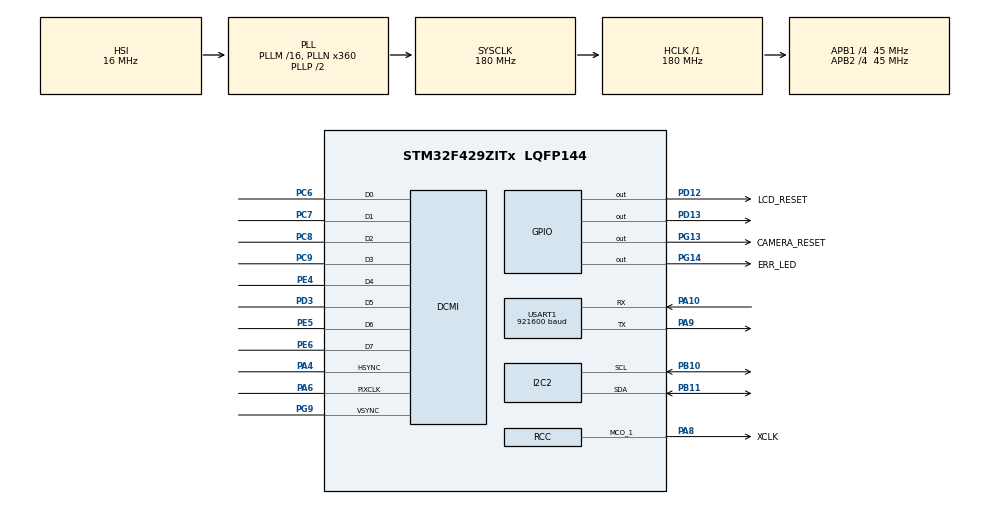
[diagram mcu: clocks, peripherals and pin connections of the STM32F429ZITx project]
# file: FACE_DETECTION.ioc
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DCMI.PCKPolarity=DCMI_PCKPOLARITY_RISING
DCMI.VSPolarity=DCMI_VSPOLARITY_HIGH
Dma.DCMI.0.Direction=DMA_PERIPH_TO_MEMORY
Dma.DCMI.0.FIFOMode=DMA_FIFOMODE_DISABLE
Dma.DCMI.0.Instance=DMA2_Stream1
Dma.DCMI.0.MemDataAlignment=DMA_MDATAALIGN_WORD
Dma.DCMI.0.MemInc=DMA_MINC_ENABLE
Dma.DCMI.0.Mode=DMA_NORMAL
Dma.DCMI.0.PeriphDataAlignment=DMA_PDATAALIGN_WORD
Dma.DCMI.0.PeriphInc=DMA_PINC_DISABLE
Dma.DCMI.0.Priority=DMA_PRIORITY_HIGH
Dma.Request0=DCMI
Mcu.Family=STM32F4
Mcu.Name=STM32F429ZITx
Mcu.Package=LQFP144
NVIC.DMA2_Stream1_IRQn=true\:0\:0\:false\:false\:true\:false\:true
NVIC.PriorityGroup=NVIC_PRIORITYGROUP_0
PA10.Mode=Asynchronous
PA10.Signal=USART1_RX
PA13.Mode=Serial_Wire
PA13.Signal=SYS_JTMS-SWDIO
PA14.Mode=Serial_Wire
PA14.Signal=SYS_JTCK-SWCLK
PA4.GPIO_Speed=GPIO_SPEED_FREQ_HIGH
PA4.Mode=Slave_8_bits_External_Synchro
PA4.Signal=DCMI_HSYNC
PA6.GPIO_Speed=GPIO_SPEED_FREQ_HIGH
PA6.Mode=Slave_8_bits_External_Synchro
PA6.Signal=DCMI_PIXCLK
PA8.GPIO_Label=XCLK
PA8.GPIO_Speed=GPIO_SPEED_FREQ_HIGH
PA8.Mode=Clock-out-1
PA8.Signal=RCC_MCO_1
PA9.Mode=Asynchronous
PA9.Signal=USART1_TX
PB10.Mode=I2C
PB10.Signal=I2C2_SCL
PB11.Mode=I2C
PB11.Signal=I2C2_SDA
PC2.Signal=FMC_SDNE0
PC6.GPIO_Speed=GPIO_SPEED_FREQ_HIGH
PC6.Mode=Slave_8_bits_External_Synchro
PC6.Signal=DCMI_D0
PC7.GPIO_Speed=GPIO_SPEED_FREQ_HIGH
PC7.Mode=Slave_8_bits_External_Synchro
PC7.Signal=DCMI_D1
PC8.GPIO_Speed=GPIO_SPEED_FREQ_HIGH
PC8.Mode=Slave_8_bits_External_Synchro
PC8.Signal=DCMI_D2
PC9.GPIO_Speed=GPIO_SPEED_FREQ_HIGH
PC9.Mode=Slave_8_bits_External_Synchro
PC9.Signal=DCMI_D3
PD12.GPIO_Label=LCD_RESET
PD12.Signal=GPIO_Output
PD13.Signal=GPIO_Output
PD3.GPIO_Speed=GPIO_SPEED_FREQ_HIGH
PD3.Mode=Slave_8_bits_External_Synchro
PD3.Signal=DCMI_D5
PE4.GPIO_Speed=GPIO_SPEED_FREQ_HIGH
PE4.Mode=Slave_8_bits_External_Synchro
PE4.Signal=DCMI_D4
PE5.GPIO_Speed=GPIO_SPEED_FREQ_HIGH
PE5.Mode=Slave_8_bits_External_Synchro
PE5.Signal=DCMI_D6
PE6.GPIO_Speed=GPIO_SPEED_FREQ_HIGH
PE6.Mode=Slave_8_bits_External_Synchro
PE6.Signal=DCMI_D7
PG13.GPIO_Label=CAMERA_RESET
PG13.Signal=GPIO_Output
PG14.GPIO_Label=ERR_LED
PG14.Signal=GPIO_Output
PG9.GPIO_Speed=GPIO_SPEED_FREQ_HIGH
PG9.Mode=Slave_8_bits_External_Synchro
PG9.Signal=DCMI_VSYNC
ProjectManager.HeapSize=0x200
ProjectManager.StackSize=0x400
ProjectManager.TargetToolchain=STM32CubeIDE
RCC.48MHZClocksFreq_Value=51428571.428571425
RCC.AHBFreq_Value=180000000
RCC.APB1CLKDivider=RCC_HCLK_DIV4
RCC.APB1Freq_Value=45000000
RCC.APB1TimFreq_Value=90000000
RCC.APB2CLKDivider=RCC_HCLK_DIV4
RCC.APB2Freq_Value=45000000
RCC.APB2TimFreq_Value=90000000
RCC.CortexFreq_Value=180000000
RCC.HCLKFreq_Value=180000000
RCC.HSE_VALUE=26000000
RCC.HSI_VALUE=16000000
RCC.LSE_VALUE=32768
RCC.PLLN=360
RCC.PLLQ=7
RCC.PLLSAIN=432
RCC.RCC_MCO1Source=RCC_MCO1SOURCE_PLLCLK
RCC.RCC_MCODiv1=RCC_MCODIV_5
RCC.SYSCLKFreq_VALUE=180000000
RCC.SYSCLKSource=RCC_SYSCLKSOURCE_PLLCLK
RCC.VCOOutputFreq_Value=360000000
USART1.BaudRate=921600
USART1.VirtualMode=VM_ASYNC
board=STM32F429I-DISC1

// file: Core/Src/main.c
/* USER CODE BEGIN Header */
/**
  ******************************************************************************
  * @file           : main.c
  * @brief          : Main program body
  ******************************************************************************
  * @attention
  *
  * Copyright (c) 2022 STMicroelectronics.
  * All rights reserved.
  *
  * This software is licensed under terms that can be found in the LICENSE file
  * in the root directory of this software component.
  * If no LICENSE file comes with this software, it is provided AS-IS.
  *
  ******************************************************************************
  */
/* USER CODE END Header */
#include "main.h"

/* USER CODE BEGIN Includes */
#include "ov7670.h"
//#include "my_ViolaJones.h"
/* USER CODE END Includes */

DCMI_HandleTypeDef hdcmi;
DMA_HandleTypeDef hdma_dcmi;

I2C_HandleTypeDef hi2c2;

UART_HandleTypeDef huart1;

/* USER CODE BEGIN PV */

uint32_t imageLen = 320*240/2;
uint32_t immagine[320*240/2];

/* USER CODE END PV */

void SystemClock_Config(void);
static void MX_GPIO_Init(void);
static void MX_DMA_Init(void);
static void MX_DCMI_Init(void);
static void MX_I2C2_Init(void);
static void MX_USART1_UART_Init(void);

int main(void)
{

  /* MCU Configuration--------------------------------------------------------*/

  /* Reset of all peripherals, Initializes the Flash interface and the Systick. */
  HAL_Init();

  /* Configure the system clock */
  SystemClock_Config();

  /* Initialize all configured peripherals */
  MX_GPIO_Init();
  MX_DMA_Init();
  MX_DCMI_Init();
  MX_I2C2_Init();
  MX_USART1_UART_Init();
  /* USER CODE BEGIN 2 */

  // inizializzazione OV7670
  if(ov7670_init(&hdcmi, &hdma_dcmi, &hi2c2) != RET_OK){
	  Error_Handler();
  }
  ov7670_config(OV7670_MODE_QVGA_RGB565); // set QVGA e RGB565 ma mode inutile perchè già presettato in OV7670_reg di default

  //uint8_t numero_facce;
  /* USER CODE END 2 */

  /* Infinite loop */
  /* USER CODE BEGIN WHILE */
  while (1)
  {
	  if(ov7670_startCap(OV7670_CAP_SINGLE_FRAME, immagine) != RET_OK)
	   	 {
	   		Error_Handler();
	   	 }
	  HAL_Delay(100);
	  ov7670_stopCap();

	  //numero_facce = (uint8_t)my_ViolaJones(immagine);

	  /*for(uint32_t i=1; i<imageLen*2; i+=2){
		  HAL_UART_Transmit(&huart1, immagine+i, 1, HAL_MAX_DELAY);
	  }*/

	  // uint32_t -> 4B da mandare su usart
	  HAL_UART_Transmit(&huart1, immagine, 4*imageLen, HAL_MAX_DELAY);

	  HAL_Delay(1000);
  }

    /* USER CODE END WHILE */

}

void SystemClock_Config(void)
{
  RCC_OscInitTypeDef RCC_OscInitStruct = {0};
  RCC_ClkInitTypeDef RCC_ClkInitStruct = {0};

  /** Configure the main internal regulator output voltage
  */
  __HAL_RCC_PWR_CLK_ENABLE();
  __HAL_PWR_VOLTAGESCALING_CONFIG(PWR_REGULATOR_VOLTAGE_SCALE1);
  /** Initializes the RCC Oscillators according to the specified parameters
  * in the RCC_OscInitTypeDef structure.
  */
  RCC_OscInitStruct.OscillatorType = RCC_OSCILLATORTYPE_HSI;
  RCC_OscInitStruct.HSIState = RCC_HSI_ON;
  RCC_OscInitStruct.HSICalibrationValue = RCC_HSICALIBRATION_DEFAULT;
  RCC_OscInitStruct.PLL.PLLState = RCC_PLL_ON;
  RCC_OscInitStruct.PLL.PLLSource = RCC_PLLSOURCE_HSI;
  RCC_OscInitStruct.PLL.PLLM = 16;
  RCC_OscInitStruct.PLL.PLLN = 360;
  RCC_OscInitStruct.PLL.PLLP = RCC_PLLP_DIV2;
  RCC_OscInitStruct.PLL.PLLQ = 7;
  if (HAL_RCC_OscConfig(&RCC_OscInitStruct) != HAL_OK)
  {
    Error_Handler();
  }
  /** Activate the Over-Drive mode
  */
  if (HAL_PWREx_EnableOverDrive() != HAL_OK)
  {
    Error_Handler();
  }
  /** Initializes the CPU, AHB and APB buses clocks
  */
  RCC_ClkInitStruct.ClockType = RCC_CLOCKTYPE_HCLK|RCC_CLOCKTYPE_SYSCLK
                              |RCC_CLOCKTYPE_PCLK1|RCC_CLOCKTYPE_PCLK2;
  RCC_ClkInitStruct.SYSCLKSource = RCC_SYSCLKSOURCE_PLLCLK;
  RCC_ClkInitStruct.AHBCLKDivider = RCC_SYSCLK_DIV1;
  RCC_ClkInitStruct.APB1CLKDivider = RCC_HCLK_DIV4;
  RCC_ClkInitStruct.APB2CLKDivider = RCC_HCLK_DIV4;

  if (HAL_RCC_ClockConfig(&RCC_ClkInitStruct, FLASH_LATENCY_5) != HAL_OK)
  {
    Error_Handler();
  }
  HAL_RCC_MCOConfig(RCC_MCO1, RCC_MCO1SOURCE_PLLCLK, RCC_MCODIV_5);
}

static void MX_DCMI_Init(void)
{

  hdcmi.Instance = DCMI;
  hdcmi.Init.SynchroMode = DCMI_SYNCHRO_HARDWARE;
  hdcmi.Init.PCKPolarity = DCMI_PCKPOLARITY_RISING;
  hdcmi.Init.VSPolarity = DCMI_VSPOLARITY_HIGH;
  hdcmi.Init.HSPolarity = DCMI_HSPOLARITY_LOW;
  hdcmi.Init.CaptureRate = DCMI_CR_ALL_FRAME;
  hdcmi.Init.ExtendedDataMode = DCMI_EXTEND_DATA_8B;
  hdcmi.Init.JPEGMode = DCMI_JPEG_DISABLE;
  if (HAL_DCMI_Init(&hdcmi) != HAL_OK)
  {
    Error_Handler();
  }

}

static void MX_I2C2_Init(void)
{

  hi2c2.Instance = I2C2;
  hi2c2.Init.ClockSpeed = 100000;
  hi2c2.Init.DutyCycle = I2C_DUTYCYCLE_2;
  hi2c2.Init.OwnAddress1 = 0;
  hi2c2.Init.AddressingMode = I2C_ADDRESSINGMODE_7BIT;
  hi2c2.Init.DualAddressMode = I2C_DUALADDRESS_DISABLE;
  hi2c2.Init.OwnAddress2 = 0;
  hi2c2.Init.GeneralCallMode = I2C_GENERALCALL_DISABLE;
  hi2c2.Init.NoStretchMode = I2C_NOSTRETCH_DISABLE;
  if (HAL_I2C_Init(&hi2c2) != HAL_OK)
  {
    Error_Handler();
  }
  /** Configure Analogue filter
  */
  if (HAL_I2CEx_ConfigAnalogFilter(&hi2c2, I2C_ANALOGFILTER_ENABLE) != HAL_OK)
  {
    Error_Handler();
  }
  /** Configure Digital filter
  */
  if (HAL_I2CEx_ConfigDigitalFilter(&hi2c2, 0) != HAL_OK)
  {
    Error_Handler();
  }

}

static void MX_USART1_UART_Init(void)
{

  huart1.Instance = USART1;
  huart1.Init.BaudRate = 921600;
  huart1.Init.WordLength = UART_WORDLENGTH_8B;
  huart1.Init.StopBits = UART_STOPBITS_1;
  huart1.Init.Parity = UART_PARITY_NONE;
  huart1.Init.Mode = UART_MODE_TX_RX;
  huart1.Init.HwFlowCtl = UART_HWCONTROL_NONE;
  huart1.Init.OverSampling = UART_OVERSAMPLING_16;
  if (HAL_UART_Init(&huart1) != HAL_OK)
  {
    Error_Handler();
  }

}

static void MX_DMA_Init(void)
{

  /* DMA controller clock enable */
  __HAL_RCC_DMA2_CLK_ENABLE();

  /* DMA interrupt init */
  /* DMA2_Stream1_IRQn interrupt configuration */
  HAL_NVIC_SetPriority(DMA2_Stream1_IRQn, 0, 0);
  HAL_NVIC_EnableIRQ(DMA2_Stream1_IRQn);

}

static void MX_GPIO_Init(void)
{
  GPIO_InitTypeDef GPIO_InitStruct = {0};

  /* GPIO Ports Clock Enable */
  __HAL_RCC_GPIOE_CLK_ENABLE();
  __HAL_RCC_GPIOC_CLK_ENABLE();
  __HAL_RCC_GPIOA_CLK_ENABLE();
  __HAL_RCC_GPIOB_CLK_ENABLE();
  __HAL_RCC_GPIOD_CLK_ENABLE();
  __HAL_RCC_GPIOG_CLK_ENABLE();

  /*Configure GPIO pin Output Level */
  HAL_GPIO_WritePin(GPIOD, LCD_RESET_Pin|GPIO_PIN_13, GPIO_PIN_RESET);

  /*Configure GPIO pin Output Level */
  HAL_GPIO_WritePin(GPIOG, CAMERA_RESET_Pin|ERR_LED_Pin, GPIO_PIN_RESET);

  /*Configure GPIO pin : PC2 */
  GPIO_InitStruct.Pin = GPIO_PIN_2;
  GPIO_InitStruct.Mode = GPIO_MODE_AF_PP;
  GPIO_InitStruct.Pull = GPIO_NOPULL;
  GPIO_InitStruct.Speed = GPIO_SPEED_FREQ_VERY_HIGH;
  GPIO_InitStruct.Alternate = GPIO_AF12_FMC;
  HAL_GPIO_Init(GPIOC, &GPIO_InitStruct);

  /*Configure GPIO pins : LCD_RESET_Pin PD13 */
  GPIO_InitStruct.Pin = LCD_RESET_Pin|GPIO_PIN_13;
  GPIO_InitStruct.Mode = GPIO_MODE_OUTPUT_PP;
  GPIO_InitStruct.Pull = GPIO_NOPULL;
  GPIO_InitStruct.Speed = GPIO_SPEED_FREQ_LOW;
  HAL_GPIO_Init(GPIOD, &GPIO_InitStruct);

  /*Configure GPIO pin : XCLK_Pin */
  GPIO_InitStruct.Pin = XCLK_Pin;
  GPIO_InitStruct.Mode = GPIO_MODE_AF_PP;
  GPIO_InitStruct.Pull = GPIO_NOPULL;
  GPIO_InitStruct.Speed = GPIO_SPEED_FREQ_HIGH;
  GPIO_InitStruct.Alternate = GPIO_AF0_MCO;
  HAL_GPIO_Init(XCLK_GPIO_Port, &GPIO_InitStruct);

  /*Configure GPIO pins : CAMERA_RESET_Pin ERR_LED_Pin */
  GPIO_InitStruct.Pin = CAMERA_RESET_Pin|ERR_LED_Pin;
  GPIO_InitStruct.Mode = GPIO_MODE_OUTPUT_PP;
  GPIO_InitStruct.Pull = GPIO_NOPULL;
  GPIO_InitStruct.Speed = GPIO_SPEED_FREQ_LOW;
  HAL_GPIO_Init(GPIOG, &GPIO_InitStruct);

}

void Error_Handler(void)
{
  /* USER CODE BEGIN Error_Handler_Debug */
  /* User can add his own implementation to report the HAL error return state */
  __disable_irq();
  while (1)
  {
	  //HAL_GPIO_WritePin(ERR_LED_GPIO_Port, ERR_LED_Pin, GPIO_PIN_SET);
  }
  /* USER CODE END Error_Handler_Debug */
}
